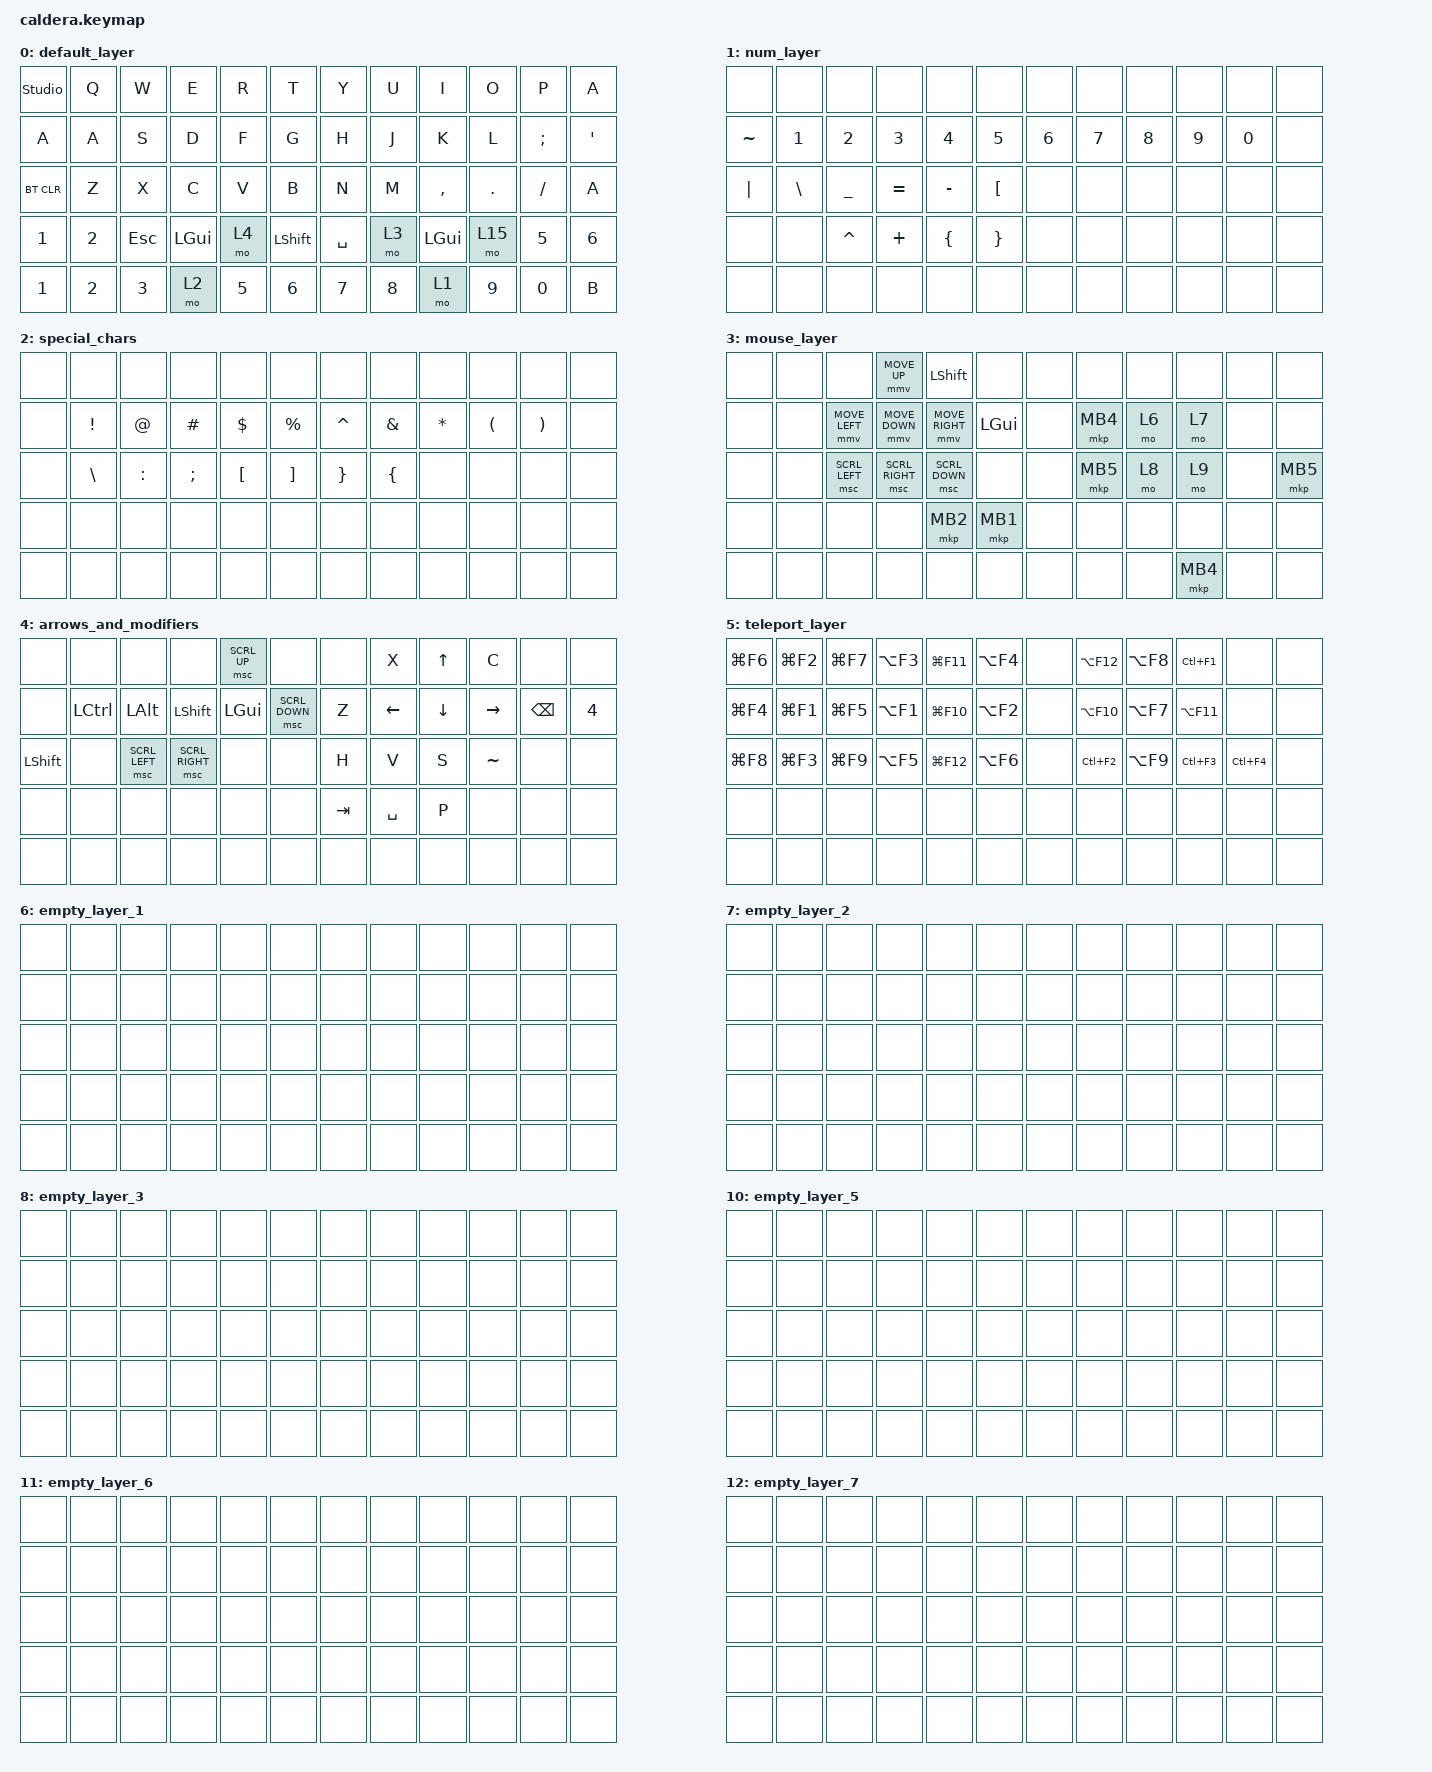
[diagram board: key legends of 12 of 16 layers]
#include <behaviors.dtsi>
#include <dt-bindings/zmk/keys.h>
#include <dt-bindings/zmk/bt.h>

#define ZMK_POINTING_DEFAULT_MOVE_VAL 1500  // default: 600
#include <dt-bindings/zmk/pointing.h>
  / {
    combos {
        compatible = "zmk,combos";
        combo_teleport {
            timeout-ms = <50>;
            key-positions = <40 43>;
            bindings = <&mo 5>;
        };
        combo_ctl {
            timeout-ms = <50>;
            key-positions = <51 56>;
            bindings = <&kp LCTRL>;
        };
        combo_shift {
            timeout-ms = <50>;
            key-positions = <41 42>;
            bindings = <&kp RET>;
        };
    };
};
/ {
    conditional_layers {
        compatible = "zmk,conditional-layers";
        fast_layer_1 {
            if-layers = <6 3>;
            then-layer = <13>;
        };

        fast_layer_2 {
            if-layers = <7 3>;
            then-layer = <14>;
        };

        fast_layer_3 {
            if-layers = <8 3>;
            then-layer = <15>;
        };

        fast_layer_4 {
            if-layers = <9 3>;
            then-layer = <16>;
        };
    };
};

/ {
    macros {
        screen_1_center: screen_1_center {
            compatible = "zmk,behavior-macro";
            #binding-cells = <0>;
            bindings = <&kp LG(F1)>;
        };

        screen_1_up: screen_1_up {
            compatible = "zmk,behavior-macro";
            #binding-cells = <0>;
            bindings = <&kp LG(F2)>;
                
        };
        screen_1_down: screen_1_down {
            compatible = "zmk,behavior-macro";
            #binding-cells = <0>;
            bindings = <&kp LG(F3)>;
        };

        screen_1_left: screen_1_left {
            compatible = "zmk,behavior-macro";
            #binding-cells = <0>;
            bindings = <&kp LG(F4)>;
        };

        screen_1_right: screen_1_right {
            compatible = "zmk,behavior-macro";
            #binding-cells = <0>;
            bindings = <&kp LG(F5)>;
        };

        screen_1_top_left: screen_1_top_left {
            compatible = "zmk,behavior-macro";
            #binding-cells = <0>;
            bindings = <&kp LG(F6)>;
        };

        screen_1_top_right: screen_1_top_right {
            compatible = "zmk,behavior-macro";
            #binding-cells = <0>;
            bindings = <&kp LG(F7)>;
        };

        screen_1_bottom_left: screen_1_bottom_left {
            compatible = "zmk,behavior-macro";
            #binding-cells = <0>;
            bindings = <&kp LG(F8)>;
        };

        screen_1_bottom_right: screen_1_bottom_right {
            compatible = "zmk,behavior-macro";
            #binding-cells = <0>;
            bindings = <&kp LG(F9)>;
        };
    };
};

/ {
        
        keymap {
                compatible = "zmk,keymap";
                default_layer {
// ---------------------------------------------------------------------------------
// |   0  |  1  |  2  |  3  |  4  |  5  |     |  6  |  7  |  8  |  9  |  10 | 11   |
// |  12  |  13 |  14 |  15 |  16 |  17 |     |  18 |  19 |  I  |  O  |  P  |  \   |
// | CAPS |  A  |  S  |  D  |  F  |  G  |     |  H  |  J  |  K  |  L  |  ;  |  ENT |
// | SHFT |  Z  |  X  |  C  |  V  |  B  |     |  N  |  M  |  ,  |  .  |  /  | APOS |
// | CTRL | ALT | GUI | SPC | SPC | SPC |     | SPC | LOW |LARW |DARW |UARW | RARW |
                        bindings = <
    &studio_unlock  &kp Q  &kp W   &kp E     &kp R  &kp T            &kp Y     &kp U  &kp I     &kp O   &kp P     &kp A
    &kp A           &kp A  &kp S   &kp D     &kp F  &kp G            &kp H     &kp J  &kp K     &kp L   &kp SEMI  &kp APOS
    &bt BT_CLR           &kp Z  &kp X   &kp C     &kp V  &kp B            &kp N     &kp M  &kp COMMA &kp DOT &kp SLASH &kp A 
    &kp N1          &kp N2 &kp ESC &kp LGUI  &mo 4  &kp LSHIFT       &kp SPACE &mo 3  &kp LGUI  &mo 15  &kp N5    &kp N6
    &kp N1          &kp N2 &kp N3  &mo 2     &kp N5 &kp N6           &kp N7    &kp N8 &mo 1     &kp N9  &kp N0    &kp B
                        >;
                };
// 1
                num_layer {
                        bindings = <
   &none      &none    &none             &none     &none        &none               &none     &none  &none    &none    &none    &none 
   &kp TILDE  &kp N1   &kp N2            &kp N3    &kp N4       &kp N5              &kp N6 &kp N7   &kp N8   &kp N9   &kp N0    &none
   &kp PIPE   &kp BSLH &kp UNDERSCORE    &kp EQUAL &kp MINUS    &kp LBKT            &none     &none  &none    &none    &none    &none 
   &none      &none    &kp CARET         &kp PLUS  &kp LBRC     &kp RBRC            &none     &none  &none    &none    &none    &none 
   &none      &none    &none             &none     &none        &none               &none     &none  &none    &none    &none    &none 
                        >;
                };
// 2
                special_chars {
                        bindings = <
   &none  &none    &none        &none             &none         &none                  &none     &none     &none    &none    &none    &none   
   &none  &kp EXCL &kp AT       &kp POUND         &kp DOLLAR    &kp PERCENT            &kp CARET &kp AMPS  &kp STAR &kp LPAR &kp RPAR &none
   &none  &kp BSLH &kp COLON    &kp SEMICOLON     &kp LBKT      &kp RBKT               &kp RBRC  &kp LBRC  &none    &none    &none    &none   
   &none  &none    &none        &none             &none         &none                  &none     &none     &none    &none    &none    &none   
   &none  &none    &none        &none             &none         &none                  &none     &none     &none    &none    &none    &none   
                        >;
                };
// 3
                mouse_layer {
                        bindings = <
   &none  &none    &none             &mmv MOVE_UP        &kp LSHFT          &none                           &none     &none     &none    &none    &none    &none   
   &none  &none    &mmv MOVE_LEFT    &mmv MOVE_DOWN      &mmv MOVE_RIGHT    &kp LGUI                        &none     &mkp MB4  &mo 6    &mo 7    &none    &none   
   &none  &none    &msc SCRL_LEFT    &msc SCRL_RIGHT     &msc SCRL_DOWN     &none                           &none     &mkp MB5  &mo 8    &mo 9    &none    &mkp MB5
   &none  &none    &none             &none               &mkp MB2           &mkp MB1                        &none     &none     &none    &none    &none    &none   
   &none  &none    &none             &none               &none              &none                           &none     &none     &none    &mkp MB4 &none    &none   
                        >;
                };
// 4 
                arrows_and_modifiers {
                        bindings = <
   &none  &none        &none             &none            &msc SCRL_UP     &none                 &none   &kp X       &kp UP       &kp C        &none     &none              
   &none  &kp LCTRL    &kp LALT          &kp LSHIFT       &kp LGUI         &msc SCRL_DOWN        &kp Z   &kp LEFT    &kp DOWN     &kp RIGHT    &kp BSPC  &kp N4           
   &kp LSHIFT  &none   &msc SCRL_LEFT    &msc SCRL_RIGHT  &none            &none                 &kp H   &kp V       &kp S        &kp TILDE    &none     &none           
   &none  &none        &none             &none            &none            &none                 &kp TAB &kp SPACE   &kp P        &none        &none     &none          
   &none  &none        &none             &none            &none            &none                 &none   &none       &none        &none        &none     &none             
                        >;
                };
// 5 
                teleport_layer {
                        bindings = <
   &kp LG(F6)        &kp LG(F2)       &kp LG(F7)       &kp LA(F3)        &kp LG(F11)  &kp LA(F4)           &none &kp LA(F12)  &kp LA(F8)  &kp LC(F1)   &none      &none 
   &kp LG(F4)        &kp LG(F1)       &kp LG(F5)       &kp LA(F1)        &kp LG(F10)  &kp LA(F2)           &none &kp LA(F10)  &kp LA(F7)  &kp LA(F11)  &none      &none 
   &kp LG(F8)        &kp LG(F3)       &kp LG(F9)       &kp LA(F5)        &kp LG(F12)  &kp LA(F6)           &none &kp LC(F2)   &kp LA(F9)  &kp LC(F3)   &kp LC(F4) &none 
   &none             &none            &none            &none             &none        &none                &none &none       &none        &none        &none      &none 
   &none             &none            &none            &none             &none        &none                &none &none       &none        &none        &none      &none 
                        >;
                };
// 6 
                empty_layer_1 {
                        bindings = <
   &none  &none    &none             &none            &none              &none                              &none     &none  &none    &none   &none    &none   
   &none  &none    &none             &none            &none              &none                              &none     &none  &none    &none   &none    &none   
   &none  &none    &none             &none            &none              &none                              &none     &none  &none    &none   &none    &none   
   &none  &none    &none             &none            &none              &none                              &none     &none  &none    &none   &none    &none   
   &none  &none    &none             &none            &none              &none                              &none     &none  &none    &none   &none    &none   
                        >;
                };
// 7
                empty_layer_2 {
                        bindings = <
   &none  &none    &none             &none            &none              &none                              &none     &none  &none    &none   &none    &none   
   &none  &none    &none             &none            &none              &none                              &none     &none  &none    &none   &none    &none   
   &none  &none    &none             &none            &none              &none                              &none     &none  &none    &none   &none    &none   
   &none  &none    &none             &none            &none              &none                              &none     &none  &none    &none   &none    &none   
   &none  &none    &none             &none            &none              &none                              &none     &none  &none    &none   &none    &none   
                        >;
                };
// 8 
                empty_layer_3 {
                        bindings = <
   &none  &none    &none             &none            &none              &none                              &none     &none  &none    &none   &none    &none   
   &none  &none    &none             &none            &none              &none                              &none     &none  &none    &none   &none    &none   
   &none  &none    &none             &none            &none              &none                              &none     &none  &none    &none   &none    &none   
   &none  &none    &none             &none            &none              &none                              &none     &none  &none    &none   &none    &none   
   &none  &none    &none             &none            &none              &none                              &none     &none  &none    &none   &none    &none   
                        >;
                };
// 9
                empty_layer_4 {
                        bindings = <
   &none  &none    &none             &none            &none              &none                              &none     &none  &none    &none   &none    &none   
   &none  &none    &none             &none            &none              &none                              &none     &none  &none    &none   &none    &none   
   &none  &none    &none             &none            &none              &none                              &none     &none  &none    &none   &none    &none   
   &none  &none    &none             &none            &none              &none                              &none     &none  &none    &none   &none    &none   
                        >;
                };
// 10
                empty_layer_5 {
                        bindings = <
   &none  &none    &none             &none            &none              &none                              &none     &none  &none   &none  &none    &none   
   &none  &none    &none             &none            &none              &none                              &none     &none  &none   &none  &none    &none   
   &none  &none    &none             &none            &none              &none                              &none     &none  &none   &none  &none    &none   
   &none  &none    &none             &none            &none              &none                              &none     &none  &none   &none  &none    &none   
   &none  &none    &none             &none            &none              &none                              &none     &none  &none   &none  &none    &none   
                        >;
                };
// 11
                empty_layer_6 {
                        bindings = <
   &none  &none    &none             &none            &none              &none                              &none     &none  &none    &none &none    &none   
   &none  &none    &none             &none            &none              &none                              &none     &none  &none    &none &none    &none   
   &none  &none    &none             &none            &none              &none                              &none     &none  &none    &none &none    &none   
   &none  &none    &none             &none            &none              &none                              &none     &none  &none    &none &none    &none   
   &none  &none    &none             &none            &none              &none                              &none     &none  &none    &none &none    &none   
                        >;
                };
// 12
                empty_layer_7 {
                        bindings = <
   &none  &none    &none             &none            &none              &none                              &none     &none  &none    &none &none    &none   
   &none  &none    &none             &none            &none              &none                              &none     &none  &none    &none &none    &none   
   &none  &none    &none             &none            &none              &none                              &none     &none  &none    &none &none    &none   
   &none  &none    &none             &none            &none              &none                              &none     &none  &none    &none &none    &none   
   &none  &none    &none             &none            &none              &none                              &none     &none  &none    &none &none    &none   
                        >;
                };
// 13
                fast_mouse_layer_1  {  
                        bindings = <
   &none  &none    &none                &mmv MOVE_Y(-4000)  &kp LSHFT          &none                     &none     &none     &none    &none    &none    &none   
   &none  &none    &mmv MOVE_X(-4000)   &mmv MOVE_Y(4000)   &mmv MOVE_X(4000)  &none                     &none     &mkp MB4  &none    &none    &none    &none   
   &none  &none    &msc SCRL_LEFT       &msc SCRL_RIGHT     &msc SCRL_DOWN     &none                     &none     &mkp MB5  &none    &none    &none    &mkp MB5
   &none  &none    &none                &none               &mkp MB2           &mkp MB1                  &none     &none     &none    &none    &none    &none   
   &none  &none    &none                &none               &none              &none                     &none     &none     &none    &none    &none    &none   
                        >;
                };
// 14
                fast_mouse_layer_2  {  
                        bindings = <
   &none  &none    &none                &mmv MOVE_Y(-200)  &kp LSHFT           &none                     &none     &none     &none    &none    &none    &none   
   &none  &none    &mmv MOVE_X(-200)   &mmv MOVE_Y(200)   &mmv MOVE_X(200)     &none                     &none     &mkp MB4  &none    &none    &none    &none   
   &none  &none    &msc SCRL_LEFT       &msc SCRL_RIGHT     &msc SCRL_DOWN     &none                     &none     &mkp MB5  &none    &none    &none    &mkp MB5
   &none  &none    &none                &none               &mkp MB2           &mkp MB1                  &none     &none     &none    &none    &none    &none   
   &none  &none    &none                &none               &none              &none                     &none     &none     &none    &none    &none    &none   
                        >;
                };
// 15
                vim_navigation {
                        bindings = <
   &none  &none    &none             &none            &none              &none                              &none     &none  &none    &none &none    &none   
   &none  &none    &none             &kp LC(D)        &kp LC(F)          &none                              &none     &none  &none    &none &none    &none   
   &none  &none    &none             &kp LC(U)        &kp LC(B)          &none                              &none     &none  &none    &none &none    &none   
   &none  &none    &none             &none            &none              &none                              &none     &none  &none    &none &none    &none   
   &none  &none    &none             &none            &none              &none                              &none     &none  &none    &none &none    &none   
                        >;
                };
        };
};


 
